# HC32M413 register map
File version: 1.0
CPU: CM4 r0p1, little endian, MPU, FPU, 4 interrupt priority bits
Registers are 32-bit, read-write, reset 0x0 unless marked. A register's access mark holds for its fields unless they carry their own. Offsets are from the block's base; [hi:lo] are bit positions; {n}, {i} and the like mark numbered series; 'fields as' and 'values as' point back to an identical list.

## MAU
Base 0x40054800
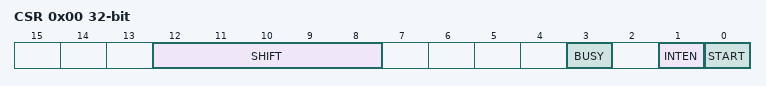
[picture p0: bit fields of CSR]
0x00 CSR
  [12:8] SHIFT, [3] BUSY, [1] INTEN, [0] START
0x04 DTR0
  [31:0] SQRT_DIN
0x0C RTR0
  [31:0] SQRT_DOUT
0x1C DTR1
  [11:0] SIN_DIN
0x20 RTR1
  [15:0] SIN_DOUT
0x24 ATAN_DIN
  [11:0] ATAN_DIN
0x28 ATAN_DOUT
  [15:0] ATAN_DOUT

## PERIC
Base 0x40054C00
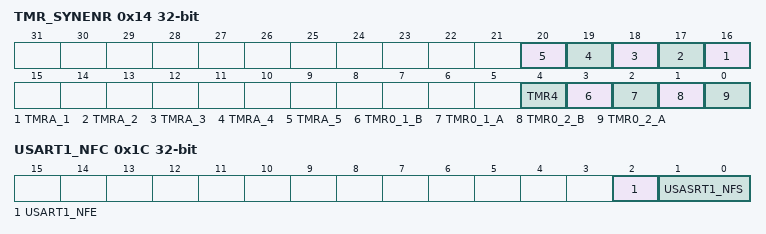
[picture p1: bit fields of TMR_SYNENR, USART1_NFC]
0x14 TMR_SYNENR
  [n+15] TMRA_{n} (n=1..5), [4] TMR4, [3] TMR0_1_B, [2] TMR0_1_A, [1] TMR0_2_B, [0] TMR0_2_A
0x1C USART1_NFC
  [2] USART1_NFE, [1:0] USASRT1_NFS

## PWC
Base 0x40054000
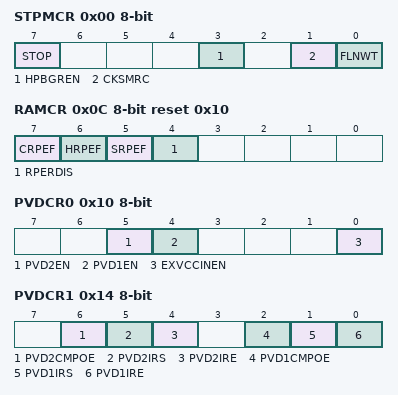
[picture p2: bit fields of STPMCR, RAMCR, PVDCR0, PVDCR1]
0x00 STPMCR 8-bit
  [7] STOP, [3] HPBGREN, [1] CKSMRC, [0] FLNWT
0x0C RAMCR 8-bit reset 0x10
  [7] CRPEF, [6] HRPEF, [5] SRPEF, [4] RPERDIS
0x10 PVDCR0 8-bit
  [5] PVD2EN, [4] PVD1EN, [0] EXVCCINEN
0x14 PVDCR1 8-bit
  [6] PVD2CMPOE, [5] PVD2IRS, [4] PVD2IRE, [2] PVD1CMPOE, [1] PVD1IRS, [0] PVD1IRE
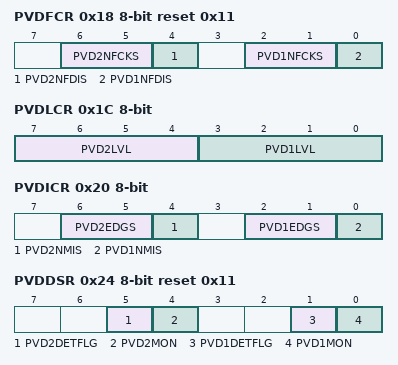
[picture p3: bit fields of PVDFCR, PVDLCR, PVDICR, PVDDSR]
0x18 PVDFCR 8-bit reset 0x11
  [6:5] PVD2NFCKS, [4] PVD2NFDIS, [2:1] PVD1NFCKS, [0] PVD1NFDIS
0x1C PVDLCR 8-bit
  [7:4] PVD2LVL, [3:0] PVD1LVL
0x20 PVDICR 8-bit
  [6:5] PVD2EDGS, [4] PVD2NMIS, [2:1] PVD1EDGS, [0] PVD1NMIS
0x24 PVDDSR 8-bit reset 0x11
  [5] PVD2DETFLG, [4] PVD2MON ro, [1] PVD1DETFLG, [0] PVD1MON ro
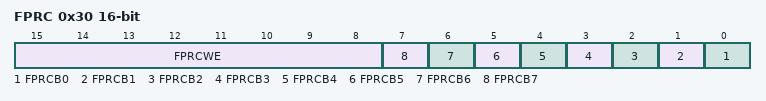
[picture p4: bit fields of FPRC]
0x30 FPRC 16-bit
  [15:8] FPRCWE, [n] FPRCB{n} (n=0..7)
0x40 DBGC 16-bit
  [0] DBGEN
0x50 LPMCSR 16-bit ro
  [0] LPMF
0x52 LPMCSCR 16-bit
  [0] LPMFC

## RMU
Base 0x40054100
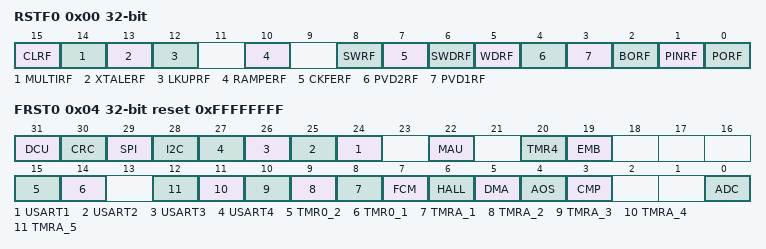
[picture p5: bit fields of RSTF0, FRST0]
0x00 RSTF0
  [15] CLRF, [14] MULTIRF, [13] XTALERF, [12] LKUPRF, [10] RAMPERF, [8] SWRF, [7] CKFERF, [6] SWDRF, [5] WDRF, [4] PVD2RF, [3] PVD1RF, [2] BORF, [1] PINRF, [0] PORF
0x04 FRST0 reset 0xFFFFFFFF
  [31] DCU, [30] CRC, [29] SPI, [28] I2C, [n+23] USART{n} (n=1..4), [22] MAU, [20] TMR4, [19] EMB, [15] TMR0_2, [14] TMR0_1, [n+7] TMRA_{n} (n=1..5), [7] FCM, [6] HALL, [5] DMA, [4] AOS, [3] CMP, [0] ADC

## SPI
Base 0x4001C000
0x00 DR
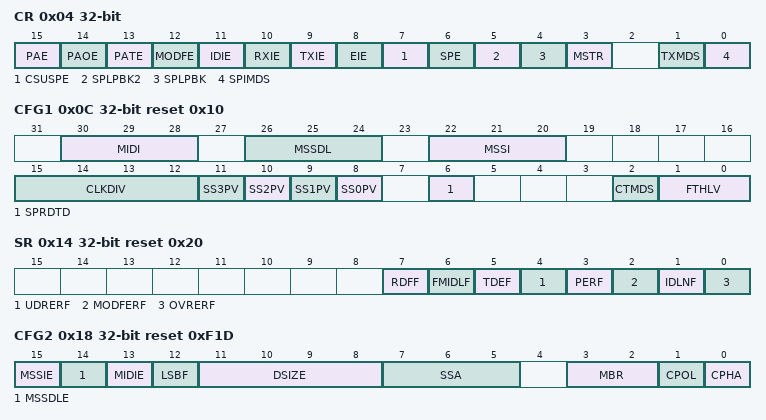
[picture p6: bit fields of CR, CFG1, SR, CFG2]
0x04 CR
  [15] PAE, [14] PAOE, [13] PATE, [12] MODFE, [11] IDIE, [10] RXIE, [9] TXIE, [8] EIE, [7] CSUSPE, [6] SPE, [5] SPLPBK2, [4] SPLPBK, [3] MSTR, [1] TXMDS, [0] SPIMDS
0x0C CFG1 reset 0x10
  [30:28] MIDI, [26:24] MSSDL, [22:20] MSSI, [15:12] CLKDIV, [n+8] SS{n}PV (n=0..3), [6] SPRDTD, [2] CTMDS, [1:0] FTHLV
0x14 SR reset 0x20
  [7] RDFF ro, [6] FMIDLF ro, [5] TDEF ro, [4] UDRERF, [3] PERF, [2] MODFERF, [1] IDLNF ro, [0] OVRERF
0x18 CFG2 reset 0xF1D
  [15] MSSIE, [14] MSSDLE, [13] MIDIE, [12] LSBF, [11:8] DSIZE, [7:5] SSA, [3:2] MBR, [1] CPOL, [0] CPHA

## SWDT
Base 0x40049400
Same registers: WDT 0x40049000
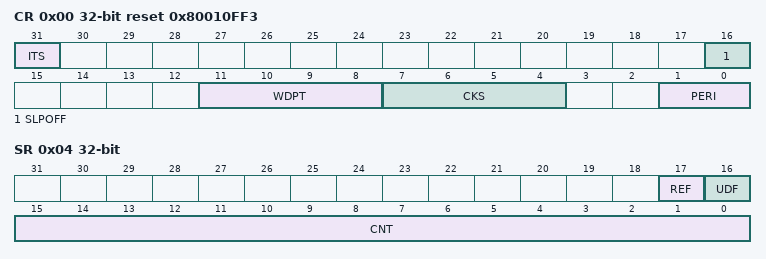
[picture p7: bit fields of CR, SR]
0x00 CR reset 0x80010FF3
  [31] ITS, [16] SLPOFF, [11:8] WDPT, [7:4] CKS, [1:0] PERI
0x04 SR
  [17] REF, [16] UDF, [15:0] CNT ro
0x08 RR
  [15:0] RF

## TMR01 — desc TMR0
Base 0x40024000
Same registers: TMR02 0x40024400
0x00 CNTAR
  [15:0] CNTA
0x04 CNTBR
  [15:0] CNTB
0x08 CMPAR reset 0xFFFF
  [15:0] CMPA
0x0C CMPBR reset 0xFFFF
  [15:0] CMPB
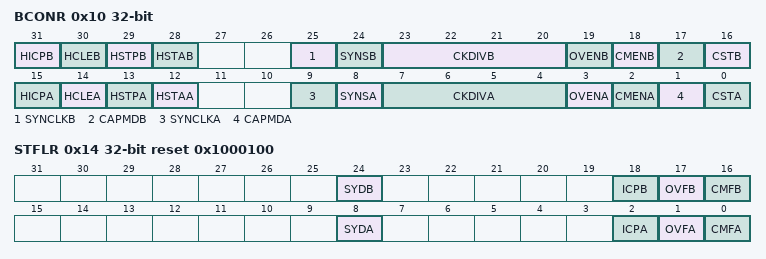
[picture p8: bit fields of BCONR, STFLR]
0x10 BCONR
  [31] HICPB, [30] HCLEB, [29] HSTPB, [28] HSTAB, [25] SYNCLKB, [24] SYNSB, [23:20] CKDIVB, [19] OVENB, [18] CMENB, [17] CAPMDB, [16] CSTB, [15] HICPA, [14] HCLEA, [13] HSTPA, [12] HSTAA, [9] SYNCLKA, [8] SYNSA, [7:4] CKDIVA, [3] OVENA, [2] CMENA, [1] CAPMDA, [0] CSTA
0x14 STFLR reset 0x1000100
  [24] SYDB ro, [18] ICPB, [17] OVFB, [16] CMFB, [8] SYDA ro, [2] ICPA, [1] OVFA, [0] CMFA

## TMRA1 — desc TMRA
Base 0x40015000
Same registers: TMRA2 0x40015400, TMRA3 0x40015800, TMRA4 0x40015C00
0x00 CNTER 16-bit
0x04 PERAR 16-bit reset 0xFFFF
0x40 CMPAR1 16-bit reset 0xFFFF
0x44 CMPAR2 16-bit reset 0xFFFF
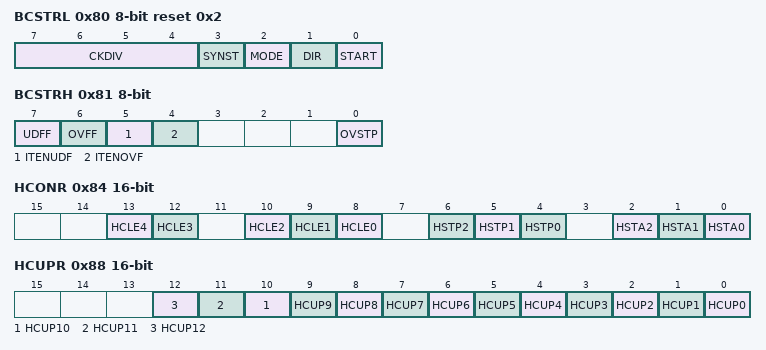
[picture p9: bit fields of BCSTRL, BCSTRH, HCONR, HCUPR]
0x80 BCSTRL 8-bit reset 0x2
  [7:4] CKDIV, [3] SYNST, [2] MODE, [1] DIR, [0] START
0x81 BCSTRH 8-bit
  [7] UDFF, [6] OVFF, [5] ITENUDF, [4] ITENOVF, [0] OVSTP
0x84 HCONR 16-bit
  [13] HCLE4, [12] HCLE3, [10] HCLE2, [9] HCLE1, [8] HCLE0, [6] HSTP2, [5] HSTP1, [4] HSTP0, [2] HSTA2, [1] HSTA1, [0] HSTA0
0x88 HCUPR 16-bit
  [n] HCUP{n} (n=0..12)
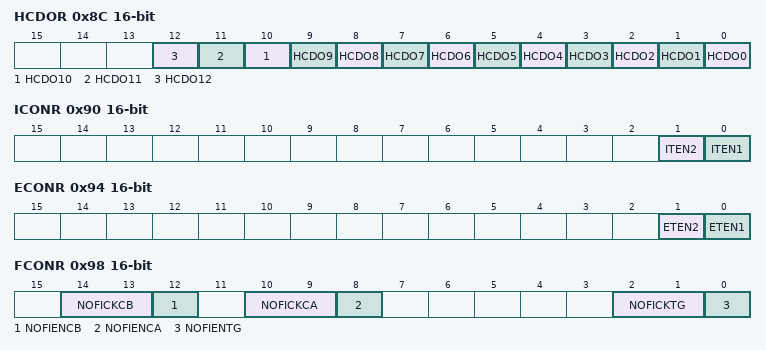
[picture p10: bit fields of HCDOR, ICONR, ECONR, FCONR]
0x8C HCDOR 16-bit
  [n] HCDO{n} (n=0..12)
0x90 ICONR 16-bit
  [1] ITEN2, [0] ITEN1
0x94 ECONR 16-bit
  [1] ETEN2, [0] ETEN1
0x98 FCONR 16-bit
  [14:13] NOFICKCB, [12] NOFIENCB, [10:9] NOFICKCA, [8] NOFIENCA, [2:1] NOFICKTG, [0] NOFIENTG
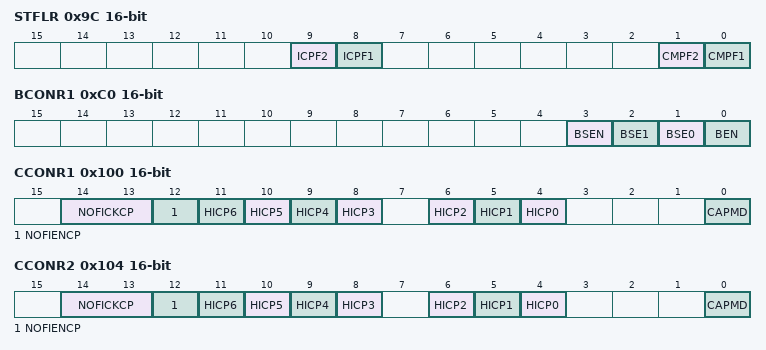
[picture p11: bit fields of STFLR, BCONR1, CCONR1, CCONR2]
0x9C STFLR 16-bit
  [9] ICPF2, [8] ICPF1, [1] CMPF2, [0] CMPF1
0xC0 BCONR1 16-bit
  [3] BSEN, [2] BSE1, [1] BSE0, [0] BEN
0x100 CCONR1 16-bit
  [14:13] NOFICKCP, [12] NOFIENCP, [n+5] HICP{n} (n=3..6), [6] HICP2, [5] HICP1, [4] HICP0, [0] CAPMD
0x104 CCONR2 16-bit
  fields as CCONR1
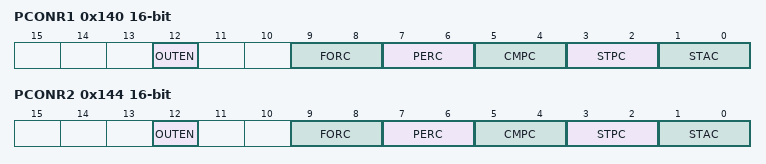
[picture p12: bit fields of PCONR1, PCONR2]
0x140 PCONR1 16-bit
  [12] OUTEN, [9:8] FORC, [7:6] PERC, [5:4] CMPC, [3:2] STPC, [1:0] STAC
0x144 PCONR2 16-bit
  fields as PCONR1

## TMRA5
Base 0x40016000
0x00 CNTER 16-bit
0x04 PERAR 16-bit reset 0xFFFF
{0x3C+4i} CMPAR{i} 16-bit reset 0xFFFF (i=1..6)
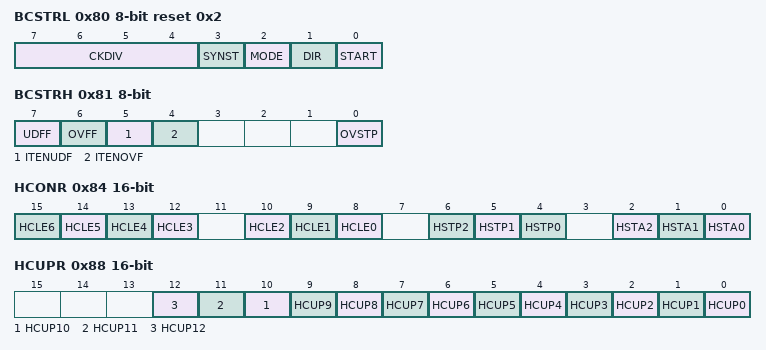
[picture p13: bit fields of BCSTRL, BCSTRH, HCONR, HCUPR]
0x80 BCSTRL 8-bit reset 0x2
  [7:4] CKDIV, [3] SYNST, [2] MODE, [1] DIR, [0] START
0x81 BCSTRH 8-bit
  [7] UDFF, [6] OVFF, [5] ITENUDF, [4] ITENOVF, [0] OVSTP
0x84 HCONR 16-bit
  [n+9] HCLE{n} (n=3..6), [10] HCLE2, [9] HCLE1, [8] HCLE0, [6] HSTP2, [5] HSTP1, [4] HSTP0, [2] HSTA2, [1] HSTA1, [0] HSTA0
0x88 HCUPR 16-bit
  [n] HCUP{n} (n=0..12)
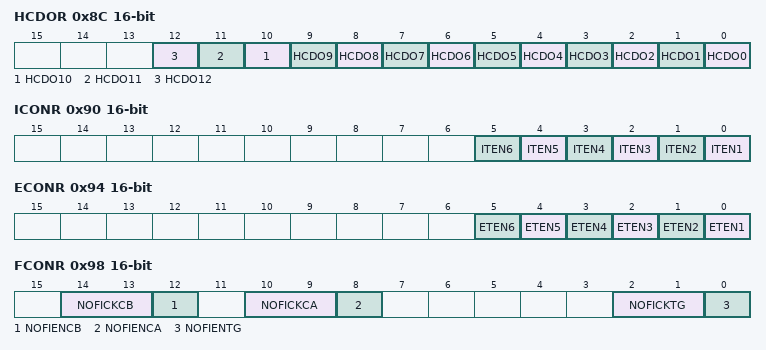
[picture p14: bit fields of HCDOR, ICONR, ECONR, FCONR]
0x8C HCDOR 16-bit
  [n] HCDO{n} (n=0..12)
0x90 ICONR 16-bit
  [n-1] ITEN{n} (n=1..6)
0x94 ECONR 16-bit
  [n-1] ETEN{n} (n=1..6)
0x98 FCONR 16-bit
  [14:13] NOFICKCB, [12] NOFIENCB, [10:9] NOFICKCA, [8] NOFIENCA, [2:1] NOFICKTG, [0] NOFIENTG
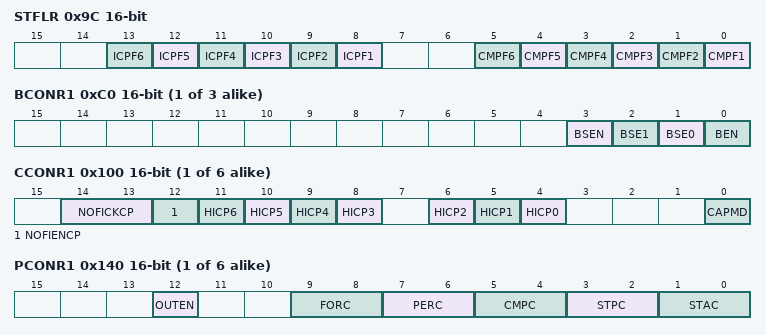
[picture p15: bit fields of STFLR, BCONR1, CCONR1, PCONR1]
0x9C STFLR 16-bit
  [n+7] ICPF{n} (n=1..6), [n-1] CMPF{n} (n=1..6)
{0xB8+8i} BCONR{i} 16-bit (i=1..3)
  [3] BSEN, [2] BSE1, [1] BSE0, [0] BEN
{0xFC+4i} CCONR{i} 16-bit (i=1..6)
  [14:13] NOFICKCP, [12] NOFIENCP, [n+5] HICP{n} (n=3..6), [6] HICP2, [5] HICP1, [4] HICP0, [0] CAPMD
{0x13C+4i} PCONR{i} 16-bit (i=1..6)
  [12] OUTEN, [9:8] FORC, [7:6] PERC, [5:4] CMPC, [3:2] STPC, [1:0] STAC
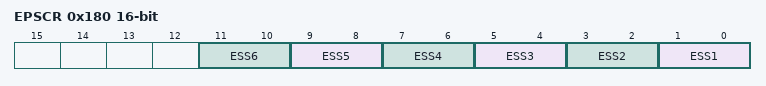
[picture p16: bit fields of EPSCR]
0x180 EPSCR 16-bit
  [2n-1:2n-2] ESS{n} (n=1..6)

## USART1 — desc USART
Base 0x4001D000
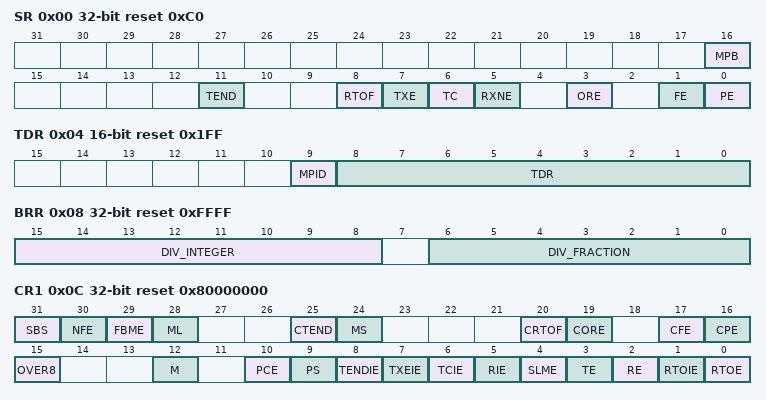
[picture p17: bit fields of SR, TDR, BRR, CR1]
0x00 SR ro reset 0xC0
  [16] MPB, [11] TEND, [8] RTOF, [7] TXE, [6] TC, [5] RXNE, [3] ORE, [1] FE, [0] PE
0x04 TDR 16-bit reset 0x1FF
  [9] MPID, [8:0] TDR
0x06 RDR 16-bit ro
  [8:0] RDR
0x08 BRR reset 0xFFFF
  [15:8] DIV_INTEGER, [6:0] DIV_FRACTION
0x0C CR1 reset 0x80000000
  [31] SBS, [30] NFE, [29] FBME, [28] ML, [25] CTEND, [24] MS, [20] CRTOF, [19] CORE, [17] CFE, [16] CPE, [15] OVER8, [12] M, [10] PCE, [9] PS, [8] TENDIE, [7] TXEIE, [6] TCIE, [5] RIE, [4] SLME, [3] TE, [2] RE, [1] RTOIE, [0] RTOE
0x10 CR2 reset 0x600
  [13] STOP, [12:11] CLKC, [0] MPE
0x14 CR3 (reset mask 0xDEE03F28)
  [31] DEP, [30] DEM, [28:25] DEA, [23:21] BCN, [15:14] TDS, [13:10] DED, [9] CTSE, [8] RTSE, [5] SCEN, [3] HDSEL
0x18 PR
  [11:8] RTOB, [4] ULBREN, [1:0] PSC

## USART2 — desc USART
Base 0x4001D400
Same registers: USART3 0x40021000, USART4 0x40021400
0x00 SR ro reset 0xC0
  [16] MPB, [12] LBM, [11] TEND, [10] LBD, [9] WKUP, [8] RTOF, [7] TXE, [6] TC, [5] RXNE, [4] BE, [3] ORE, [1] FE, [0] PE
0x04 TDR 16-bit reset 0x1FF
  [9] MPID, [8:0] TDR
0x06 RDR 16-bit ro
  [8:0] RDR
0x08 BRR reset 0xFFFF
  [15:8] DIV_INTEGER, [6:0] DIV_FRACTION
0x0C CR1 reset 0x80000000
  [31] SBS, [30] NFE, [29] FBME, [28] ML, [26] CLBM, [25] CTEND, [24] MS, [23] CLBD, [22] CWKUP, [21] CBE, [20] CRTOF, [19] CORE, [17] CFE, [16] CPE, [15] OVER8, [12] M, [10] PCE, [9] PS, [8] TENDIE, [7] TXEIE, [6] TCIE, [5] RIE, [4] SLME, [3] TE, [2] RE, [1] RTOIE, [0] RTOE
0x10 CR2 reset 0x600
  [19] LBMIE, [17] SBKM, [16] SBK, [15] UATSBKE, [14] LINEN, [13] STOP, [12:11] CLKC, [8] WKUPE, [7:6] SBKL, [5] LBDL, [4] LBDIE, [3] BEE, [2] BEIE, [1] WKUPIE, [0] MPE
0x14 CR3 (reset mask 0xDE003F18)
  [31] DEP, [30] DEM, [28:25] DEA, [15:14] TDS, [13:10] DED, [9] CTSE, [8] RTSE, [4] LOOP, [3] HDSEL
0x18 PR
  [11:8] RTOB, [4] ULBREN, [3:2] LBMPSC, [1:0] PSC
0x1C LBMC ro
  [15:0] LBMC
